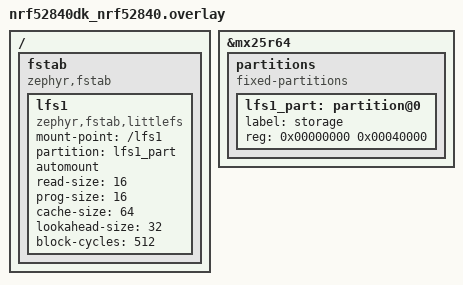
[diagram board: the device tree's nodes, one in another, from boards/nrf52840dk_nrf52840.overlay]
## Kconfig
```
# Copyright (c) 2019 Peter Bigot Consulting, LLC
# SPDX-License-Identifier: Apache-2.0

mainmenu "littlefs sample"

config APP_WIPE_STORAGE
	bool "Option to clear the flash area before mounting"
	help
	  Use this to force an existing file system to be created.

choice
	prompt "Storage backend type used by the application"
	default APP_LITTLEFS_STORAGE_FLASH
	help
	  Specify the type of storage backend.

config APP_LITTLEFS_STORAGE_FLASH
	bool "Use flash memory backend"

config APP_LITTLEFS_STORAGE_BLK_SDMMC
	bool "Use block device (e.g. SD MMC) backend"
endchoice

source "Kconfig.zephyr"
```

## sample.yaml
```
sample:
  name: littlefs filesystem sample
tests:
  sample.filesystem.littlefs:
    build_only: true
    platform_allow: nrf52840dk_nrf52840 particle_xenon disco_l475_iot1
      mimxrt685_evk_cm33 mimxrt1060_evk mimxrt1064_evk qemu_x86 native_posix
      mimxrt1160_evk_cm7
    tags: filesystem
```

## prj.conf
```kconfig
#
# Copyright (c) 2019 Peter Bigot Consulting, LLC
#
# SPDX-License-Identifier: Apache-2.0
#

# Optionally force the file system to be recreated
#CONFIG_APP_WIPE_STORAGE=y

# fs_dirent structures are big.
CONFIG_MAIN_STACK_SIZE=2048

# Let __ASSERT do its job
CONFIG_DEBUG=y

CONFIG_LOG=y
CONFIG_LOG_MODE_MINIMAL=y

CONFIG_FLASH=y
CONFIG_FLASH_MAP=y
CONFIG_FLASH_PAGE_LAYOUT=y

CONFIG_FILE_SYSTEM=y
CONFIG_FILE_SYSTEM_LITTLEFS=y

CONFIG_DEBUG_OPTIMIZATIONS=y
```

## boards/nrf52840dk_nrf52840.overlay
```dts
/*
 * Copyright (c) 2019 Peter Bigot Consulting, LLC
 *
 * SPDX-License-Identifier: Apache-2.0
 */

/delete-node/ &storage_partition;

/ {
	fstab {
		compatible = "zephyr,fstab";
		lfs1: lfs1 {
			compatible = "zephyr,fstab,littlefs";
			mount-point = "/lfs1";
			partition = <&lfs1_part>;
			automount;
			read-size = <16>;
			prog-size = <16>;
			cache-size = <64>;
			lookahead-size = <32>;
			block-cycles = <512>;
		};
	};
};

&mx25r64 {
	partitions {
		compatible = "fixed-partitions";
		#address-cells = <1>;
		#size-cells = <1>;

		lfs1_part: partition@0 {
			label = "storage";
			reg = <0x00000000 0x00040000>;
		};
	};
};
```

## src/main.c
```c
/*
 * Copyright (c) 2022 Lukasz Majewski, DENX Software Engineering GmbH
 * Copyright (c) 2019 Peter Bigot Consulting, LLC
 *
 * SPDX-License-Identifier: Apache-2.0
 */

/* Sample which uses the filesystem API with littlefs */

#include <stdio.h>

#include <zephyr.h>
#include <device.h>
#include <fs/fs.h>
#include <fs/littlefs.h>
#include <logging/log.h>
#include <storage/flash_map.h>
#include <errno.h>

LOG_MODULE_REGISTER(main);

struct fs_file_t file;

uint8_t data[] = "Wake up \n \
(Wake up) \n \
Grab a brush and put a little make-up \n \
Hide the scars to fade away the shake-up \n \
(Hide the scars to fade away the...) \n \
Why'd you leave the keys upon the table? \n \
Here you go create another fable \n \
You wanted to \n \
Grab a brush and put a little makeup \n \
You wanted to \n \
Hide the scars to fade away the shake-up \n \
You wanted to \n \
Why'd you leave the keys upon the table? \n \
You wanted to \n \
I don't think you trust \n \
In... My... Self-righteous suicide \n \
I... Cry... When angels deserve to die \n \
Wake up \n \
(Wake up) \n \
Grab a brush and put a little make-up \n \
Hide the scars to fade away the \n \
(Hide the scars to fade away the shake-up) \n \
Why'd you leave the keys upon the table? \n \
Here you go create another fable \n \
You wanted to \n \
Grab a brush and put a little make-up \n \
You wanted to \n \
Hide the scars to fade away the shake-up \n \
You wanted to \n \
Why'd you leave the keys upon the table? \n \
You wanted to \n \
I don't think you trust \n \
In... My... Self-righteous suicide \n \
I... Cry... When angels deserve to die \n \
In, my, Self-righteous suicide \n \
I, cry, when angels deserve to die \n \
Father (father) \n \
Father (father) \n \
Father (father) \n \
Father (father) \n \
Father, into your hands I commend my spirit \n \
Father, into your hands \n \
Why have you forsaken me? \n \
In your eyes forsaken me \n \
In your thoughts forsaken me \n \
In your heart forsaken me, oh \n \
Trust in my self-righteous suicide \n \
I cry when angels deserve to die \n \
In my self-righteous suicide \n \
I cry when angels deserve to die";
uint8_t data2[255];

int write_stuff(struct fs_file_t *file, void *data, int size)
{
	int ret;
	ret = fs_seek(file, 0, FS_SEEK_SET);
	if (ret<0) {
		LOG_ERR("seek fail!");
	}
	ret = fs_write(file, data, size);
	if (ret<0) {
		LOG_ERR("write fail!");
	}
	LOG_INF("write %d bytes", ret);
	fs_sync(file);
	return ret;
}

int read_stuff(struct fs_file_t *file, void *data, int size)
{
	int ret, c = 0;
	ret = fs_seek(file, 0, FS_SEEK_SET);
	if (ret<0) {
		LOG_ERR("seek fail!");
	}
	do {
		ret = fs_read(file, data, size);
		LOG_INF("read; %s", (char*) data);
		c+=ret;
	} while (ret > 0);
	if (ret<0) {
		LOG_ERR("read fail!");
		return ret;
	}

	LOG_INF("read %d bytes", c);
	return c;
}

void main(void)
{
	int ret;
	fs_file_t_init(&file);

	ret = fs_open(&file, "/lfs1/test", FS_O_CREATE | FS_O_RDWR);
	if (ret<0) {
		LOG_ERR("open fail!");
	}
	write_stuff(&file, data, sizeof(data));
	read_stuff(&file, data2, sizeof(data2));
}
```
